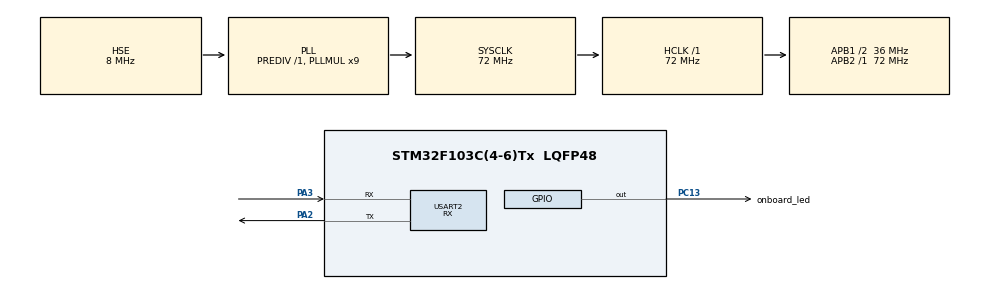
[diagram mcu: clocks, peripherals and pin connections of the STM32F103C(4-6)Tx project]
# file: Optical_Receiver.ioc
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Mcu.Family=STM32F1
Mcu.Name=STM32F103C(4-6)Tx
Mcu.Package=LQFP48
NVIC.PriorityGroup=NVIC_PRIORITYGROUP_4
NVIC.USART2_IRQn=true\:0\:0\:false\:false\:true\:true\:true\:true
PA13.Mode=Serial_Wire
PA13.Signal=SYS_JTMS-SWDIO
PA14.Mode=Serial_Wire
PA14.Signal=SYS_JTCK-SWCLK
PA2.Mode=IrDA
PA2.Signal=USART2_TX
PA3.Mode=IrDA
PA3.Signal=USART2_RX
PC13-TAMPER-RTC.GPIO_Label=onboard_led
PC13-TAMPER-RTC.Signal=GPIO_Output
PD0-OSC_IN.Mode=HSE-External-Oscillator
PD0-OSC_IN.Signal=RCC_OSC_IN
PD1-OSC_OUT.Mode=HSE-External-Oscillator
PD1-OSC_OUT.Signal=RCC_OSC_OUT
ProjectManager.HeapSize=0x200
ProjectManager.StackSize=0x400
ProjectManager.TargetToolchain=CMake
RCC.AHBFreq_Value=72000000
RCC.APB1CLKDivider=RCC_HCLK_DIV2
RCC.APB1Freq_Value=36000000
RCC.APB1TimFreq_Value=72000000
RCC.APB2Freq_Value=72000000
RCC.APB2TimFreq_Value=72000000
RCC.HCLKFreq_Value=72000000
RCC.PLLMUL=RCC_PLL_MUL9
RCC.PLLSourceVirtual=RCC_PLLSOURCE_HSE
RCC.SYSCLKFreq_VALUE=72000000
RCC.SYSCLKSource=RCC_SYSCLKSOURCE_PLLCLK
RCC.USBFreq_Value=72000000
USART2.Mode=MODE_RX
USART2.VirtualMode=VM_IRDA
board=custom

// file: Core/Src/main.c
/* USER CODE BEGIN Header */
/**
  ******************************************************************************
  * @file           : main.c
  * @brief          : Main program body
  ******************************************************************************
  * @attention
  *
  * Copyright (c) 2026 STMicroelectronics.
  * All rights reserved.
  *
  * This software is licensed under terms that can be found in the LICENSE file
  * in the root directory of this software component.
  * If no LICENSE file comes with this software, it is provided AS-IS.
  *
  ******************************************************************************
  */
/* USER CODE END Header */
#include "main.h"

IRDA_HandleTypeDef hirda2;

/* USER CODE BEGIN PV */
uint8_t rxBuffer[1];
uint8_t newDataFlag = 0;
uint8_t receivedData = 0;
/* USER CODE END PV */

void SystemClock_Config(void);
static void MX_GPIO_Init(void);
static void MX_USART2_IRDA_Init(void);

int main(void)
{

  /* MCU Configuration--------------------------------------------------------*/

  /* Reset of all peripherals, Initializes the Flash interface and the Systick. */
  HAL_Init();

  /* Configure the system clock */
  SystemClock_Config();

  /* Initialize all configured peripherals */
  MX_GPIO_Init();
  MX_USART2_IRDA_Init();
  /* USER CODE BEGIN 2 */
  HAL_IRDA_Receive_IT(&hirda2, rxBuffer, 1);
  /* USER CODE END 2 */

  /* Infinite loop */
  /* USER CODE BEGIN WHILE */
  while (1)
  {
    if (newDataFlag)
    {
      receivedData = rxBuffer[0];
      HAL_IRDA_Receive_IT(&hirda2, rxBuffer, 1);
      newDataFlag = 0;
    }

    HAL_GPIO_TogglePin(onboard_led_GPIO_Port, onboard_led_Pin);
    HAL_Delay(500);
    /* USER CODE END WHILE */

  }
}

void SystemClock_Config(void)
{
  RCC_OscInitTypeDef RCC_OscInitStruct = {0};
  RCC_ClkInitTypeDef RCC_ClkInitStruct = {0};

  /** Initializes the RCC Oscillators according to the specified parameters
  * in the RCC_OscInitTypeDef structure.
  */
  RCC_OscInitStruct.OscillatorType = RCC_OSCILLATORTYPE_HSE;
  RCC_OscInitStruct.HSEState = RCC_HSE_ON;
  RCC_OscInitStruct.HSEPredivValue = RCC_HSE_PREDIV_DIV1;
  RCC_OscInitStruct.HSIState = RCC_HSI_ON;
  RCC_OscInitStruct.PLL.PLLState = RCC_PLL_ON;
  RCC_OscInitStruct.PLL.PLLSource = RCC_PLLSOURCE_HSE;
  RCC_OscInitStruct.PLL.PLLMUL = RCC_PLL_MUL9;
  if (HAL_RCC_OscConfig(&RCC_OscInitStruct) != HAL_OK)
  {
    Error_Handler();
  }

  /** Initializes the CPU, AHB and APB buses clocks
  */
  RCC_ClkInitStruct.ClockType = RCC_CLOCKTYPE_HCLK|RCC_CLOCKTYPE_SYSCLK
                              |RCC_CLOCKTYPE_PCLK1|RCC_CLOCKTYPE_PCLK2;
  RCC_ClkInitStruct.SYSCLKSource = RCC_SYSCLKSOURCE_PLLCLK;
  RCC_ClkInitStruct.AHBCLKDivider = RCC_SYSCLK_DIV1;
  RCC_ClkInitStruct.APB1CLKDivider = RCC_HCLK_DIV2;
  RCC_ClkInitStruct.APB2CLKDivider = RCC_HCLK_DIV1;

  if (HAL_RCC_ClockConfig(&RCC_ClkInitStruct, FLASH_LATENCY_2) != HAL_OK)
  {
    Error_Handler();
  }
}

static void MX_USART2_IRDA_Init(void)
{

  hirda2.Instance = USART2;
  hirda2.Init.BaudRate = 115200;
  hirda2.Init.WordLength = IRDA_WORDLENGTH_8B;
  hirda2.Init.Parity = IRDA_PARITY_NONE;
  hirda2.Init.Mode = IRDA_MODE_RX;
  hirda2.Init.Prescaler = 1;
  hirda2.Init.IrDAMode = IRDA_POWERMODE_NORMAL;
  if (HAL_IRDA_Init(&hirda2) != HAL_OK)
  {
    Error_Handler();
  }

}

static void MX_GPIO_Init(void)
{
  GPIO_InitTypeDef GPIO_InitStruct = {0};

  /* GPIO Ports Clock Enable */
  __HAL_RCC_GPIOC_CLK_ENABLE();
  __HAL_RCC_GPIOD_CLK_ENABLE();
  __HAL_RCC_GPIOA_CLK_ENABLE();

  /*Configure GPIO pin Output Level */
  HAL_GPIO_WritePin(onboard_led_GPIO_Port, onboard_led_Pin, GPIO_PIN_RESET);

  /*Configure GPIO pin : onboard_led_Pin */
  GPIO_InitStruct.Pin = onboard_led_Pin;
  GPIO_InitStruct.Mode = GPIO_MODE_OUTPUT_PP;
  GPIO_InitStruct.Pull = GPIO_NOPULL;
  GPIO_InitStruct.Speed = GPIO_SPEED_FREQ_LOW;
  HAL_GPIO_Init(onboard_led_GPIO_Port, &GPIO_InitStruct);

}

/* USER CODE BEGIN 4 */
/**
  * @brief  Rx Transfer complete callback.
  * @param  hirda  Pointer to a IRDA_HandleTypeDef structure that contains
  *                the configuration information for the specified IRDA module.
  * @retval None
  */
void HAL_IRDA_RxCpltCallback(IRDA_HandleTypeDef *hirda)
{
  if (hirda->Instance == USART2)
  {
    newDataFlag = 1;
  }
}
/* USER CODE END 4 */

void Error_Handler(void)
{
  __disable_irq();
  while (1)
  {
  }
}
